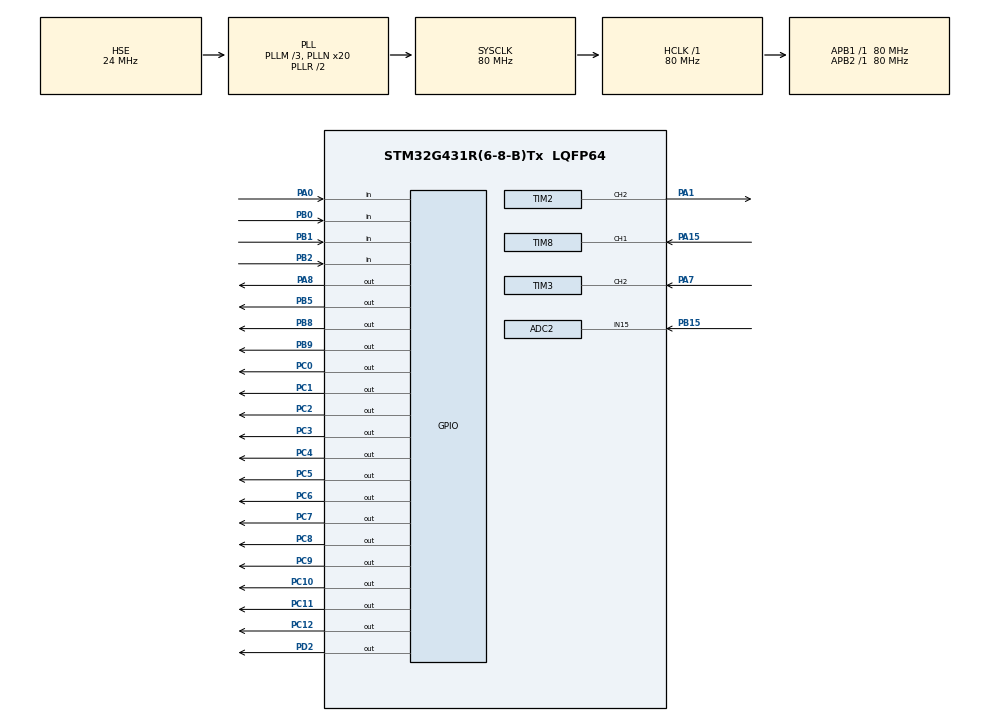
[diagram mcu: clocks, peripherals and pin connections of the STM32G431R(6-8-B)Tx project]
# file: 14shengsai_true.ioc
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ADC2.Channel-0\#ChannelRegularConversion=ADC_CHANNEL_15
ADC2.ClockPrescaler=ADC_CLOCK_ASYNC_DIV4
ADC2.ContinuousConvMode=ENABLE
ADC2.DMAContinuousRequests=ENABLE
ADC2.NbrOfConversionFlag=1
ADC2.OffsetNumber-0\#ChannelRegularConversion=ADC_OFFSET_NONE
ADC2.Rank-0\#ChannelRegularConversion=1
ADC2.SamplingTime-0\#ChannelRegularConversion=ADC_SAMPLETIME_2CYCLES_5
Dma.ADC2.0.Direction=DMA_PERIPH_TO_MEMORY
Dma.ADC2.0.EventEnable=DISABLE
Dma.ADC2.0.Instance=DMA1_Channel2
Dma.ADC2.0.MemDataAlignment=DMA_MDATAALIGN_WORD
Dma.ADC2.0.MemInc=DMA_MINC_ENABLE
Dma.ADC2.0.Mode=DMA_CIRCULAR
Dma.ADC2.0.PeriphDataAlignment=DMA_PDATAALIGN_WORD
Dma.ADC2.0.PeriphInc=DMA_PINC_DISABLE
Dma.ADC2.0.Polarity=HAL_DMAMUX_REQ_GEN_RISING
Dma.ADC2.0.Priority=DMA_PRIORITY_MEDIUM
Dma.ADC2.0.RequestNumber=1
Dma.ADC2.0.SignalID=NONE
Dma.ADC2.0.SyncEnable=DISABLE
Dma.ADC2.0.SyncPolarity=HAL_DMAMUX_SYNC_NO_EVENT
Dma.ADC2.0.SyncRequestNumber=1
Dma.ADC2.0.SyncSignalID=NONE
Dma.Request0=ADC2
Dma.Request1=TIM3_CH2
Dma.Request2=TIM8_CH1
Dma.TIM3_CH2.1.Direction=DMA_PERIPH_TO_MEMORY
Dma.TIM3_CH2.1.EventEnable=DISABLE
Dma.TIM3_CH2.1.Instance=DMA1_Channel1
Dma.TIM3_CH2.1.MemDataAlignment=DMA_MDATAALIGN_WORD
Dma.TIM3_CH2.1.MemInc=DMA_MINC_ENABLE
Dma.TIM3_CH2.1.Mode=DMA_CIRCULAR
Dma.TIM3_CH2.1.PeriphDataAlignment=DMA_PDATAALIGN_WORD
Dma.TIM3_CH2.1.PeriphInc=DMA_PINC_DISABLE
Dma.TIM3_CH2.1.Polarity=HAL_DMAMUX_REQ_GEN_RISING
Dma.TIM3_CH2.1.Priority=DMA_PRIORITY_LOW
Dma.TIM3_CH2.1.RequestNumber=1
Dma.TIM3_CH2.1.SignalID=NONE
Dma.TIM3_CH2.1.SyncEnable=DISABLE
Dma.TIM3_CH2.1.SyncPolarity=HAL_DMAMUX_SYNC_NO_EVENT
Dma.TIM3_CH2.1.SyncRequestNumber=1
Dma.TIM3_CH2.1.SyncSignalID=NONE
Dma.TIM8_CH1.2.Direction=DMA_PERIPH_TO_MEMORY
Dma.TIM8_CH1.2.EventEnable=DISABLE
Dma.TIM8_CH1.2.Instance=DMA1_Channel3
Dma.TIM8_CH1.2.MemDataAlignment=DMA_MDATAALIGN_WORD
Dma.TIM8_CH1.2.MemInc=DMA_MINC_ENABLE
Dma.TIM8_CH1.2.Mode=DMA_CIRCULAR
Dma.TIM8_CH1.2.PeriphDataAlignment=DMA_PDATAALIGN_WORD
Dma.TIM8_CH1.2.PeriphInc=DMA_PINC_DISABLE
Dma.TIM8_CH1.2.Polarity=HAL_DMAMUX_REQ_GEN_RISING
Dma.TIM8_CH1.2.Priority=DMA_PRIORITY_LOW
Dma.TIM8_CH1.2.RequestNumber=1
Dma.TIM8_CH1.2.SignalID=NONE
Dma.TIM8_CH1.2.SyncEnable=DISABLE
Dma.TIM8_CH1.2.SyncPolarity=HAL_DMAMUX_SYNC_NO_EVENT
Dma.TIM8_CH1.2.SyncRequestNumber=1
Dma.TIM8_CH1.2.SyncSignalID=NONE
Mcu.Family=STM32G4
Mcu.Name=STM32G431R(6-8-B)Tx
Mcu.Package=LQFP64
NVIC.ADC1_2_IRQn=true\:0\:0\:false\:false\:true\:true\:true\:true
NVIC.DMA1_Channel1_IRQn=true\:0\:0\:false\:false\:true\:false\:true\:true
NVIC.DMA1_Channel2_IRQn=true\:0\:0\:false\:false\:true\:false\:true\:true
NVIC.DMA1_Channel3_IRQn=true\:0\:0\:false\:false\:true\:false\:true\:true
NVIC.PriorityGroup=NVIC_PRIORITYGROUP_4
PA0.GPIO_PuPd=GPIO_PULLUP
PA0.Signal=GPIO_Input
PA1.Signal=S_TIM2_CH2
PA15.Signal=S_TIM8_CH1
PA7.Signal=S_TIM3_CH2
PA8.Signal=GPIO_Output
PB0.GPIO_PuPd=GPIO_PULLUP
PB0.Signal=GPIO_Input
PB1.GPIO_PuPd=GPIO_PULLUP
PB1.Signal=GPIO_Input
PB15.Mode=IN15-Single-Ended
PB15.Signal=ADC2_IN15
PB2.GPIO_PuPd=GPIO_PULLUP
PB2.Signal=GPIO_Input
PB5.Signal=GPIO_Output
PB8-BOOT0.Signal=GPIO_Output
PB9.Signal=GPIO_Output
PC0.Signal=GPIO_Output
PC1.Signal=GPIO_Output
PC10.Signal=GPIO_Output
PC11.Signal=GPIO_Output
PC12.Signal=GPIO_Output
PC2.Signal=GPIO_Output
PC3.Signal=GPIO_Output
PC4.Signal=GPIO_Output
PC5.Signal=GPIO_Output
PC6.Signal=GPIO_Output
PC7.Signal=GPIO_Output
PC8.Signal=GPIO_Output
PC9.Signal=GPIO_Output
PD2.Signal=GPIO_Output
PF0-OSC_IN.Mode=HSE-External-Oscillator
PF0-OSC_IN.Signal=RCC_OSC_IN
PF1-OSC_OUT.Mode=HSE-External-Oscillator
PF1-OSC_OUT.Signal=RCC_OSC_OUT
ProjectManager.HeapSize=0x200
ProjectManager.StackSize=0x400
ProjectManager.TargetToolchain=MDK-ARM V5.32
RCC.ADC12Freq_Value=80000000
RCC.AHBFreq_Value=80000000
RCC.APB1Freq_Value=80000000
RCC.APB1TimFreq_Value=80000000
RCC.APB2Freq_Value=80000000
RCC.APB2TimFreq_Value=80000000
RCC.CortexFreq_Value=80000000
RCC.EXTERNAL_CLOCK_VALUE=12288000
RCC.HCLKFreq_Value=80000000
RCC.HSE_VALUE=24000000
RCC.HSI48_VALUE=48000000
RCC.HSI_VALUE=16000000
RCC.LSE_VALUE=32768
RCC.PLLM=RCC_PLLM_DIV3
RCC.PLLN=20
RCC.PLLSourceVirtual=RCC_PLLSOURCE_HSE
RCC.SYSCLKFreq_VALUE=80000000
RCC.SYSCLKSource=RCC_SYSCLKSOURCE_PLLCLK
RCC.USBFreq_Value=80000000
RCC.VCOOutputFreq_Value=160000000
SH.S_TIM2_CH2.0=TIM2_CH2,PWM Generation2 CH2
SH.S_TIM3_CH2.0=TIM3_CH2,TriggerSource_TI2FP2
SH.S_TIM3_CH2.1=TIM3_CH2,Input_Capture2_from_TI2
SH.S_TIM8_CH1.0=TIM8_CH1,TriggerSource_TI1FP1
SH.S_TIM8_CH1.1=TIM8_CH1,Input_Capture1_from_TI1
TIM2.Channel-PWM\ Generation2\ CH2=TIM_CHANNEL_2
TIM2.PeriodNoDither=999
TIM2.Prescaler=79
TIM2.PulseNoDither_2=10
TIM3.Channel-Input_Capture2_from_TI2=TIM_CHANNEL_2
TIM3.Prescaler=79
TIM8.Channel-Input_Capture1_from_TI1=TIM_CHANNEL_1
TIM8.Prescaler=79
VP_SYS_VS_DBSignals.Mode=DisableDeadBatterySignals
VP_TIM2_VS_ClockSourceINT.Mode=Internal
VP_TIM3_VS_ClockSourceINT.Mode=Internal
VP_TIM3_VS_ControllerModeReset.Mode=Reset Mode
VP_TIM8_VS_ClockSourceINT.Mode=Internal
VP_TIM8_VS_ControllerModeReset.Mode=Reset Mode
board=custom

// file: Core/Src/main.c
/* USER CODE BEGIN Header */
/**
  ******************************************************************************
  * @file           : main.c
  * @brief          : Main program body
  ******************************************************************************
  * @attention
  *
  * Copyright (c) 2025 STMicroelectronics.
  * All rights reserved.
  *
  * This software is licensed under terms that can be found in the LICENSE file
  * in the root directory of this software component.
  * If no LICENSE file comes with this software, it is provided AS-IS.
  *
  ******************************************************************************
  */
/* USER CODE END Header */
#include "main.h"
#include "adc.h"
#include "dma.h"
#include "tim.h"
#include "gpio.h"
#include "bsp.h"

void SystemClock_Config(void);

int main(void)
{

  /* MCU Configuration--------------------------------------------------------*/

  /* Reset of all peripherals, Initializes the Flash interface and the Systick. */
  HAL_Init();

  /* Configure the system clock */
  SystemClock_Config();

  /* Initialize all configured peripherals */
  MX_GPIO_Init();
  MX_DMA_Init();
  MX_ADC2_Init();
  MX_TIM2_Init();
  MX_TIM3_Init();
  MX_TIM8_Init();
	scheduler_init();
  /* USER CODE BEGIN 2 */
LCD_Init();
LCD_Clear(Black);
LCD_SetBackColor(Black);
LCD_SetTextColor(White);
HAL_ADC_Start_DMA(&hadc2,(uint32_t*)&dma_buff[0][0],30);
HAL_TIM_IC_Start_DMA(&htim3,TIM_CHANNEL_2,tim_ic_buffer[0],64);//pa7,测量接收输入的频率
//HAL_TIM_IC_Start_DMA(&htim8,TIM_CHANNEL_1,tim_ic_buffer[0],64);//pa7换成了pa15
HAL_TIM_PWM_Start(&htim2,TIM_CHANNEL_2);//PA1,pwm输出
  /* USER CODE END 2 */

  /* Infinite loop */
  while (1)
  {
//key_proc();
//lcd_proc();
//ic_proc();
//adc_proc();
//led_proc();
		scheduler_run();
  }
}

void SystemClock_Config(void)
{
  RCC_OscInitTypeDef RCC_OscInitStruct = {0};
  RCC_ClkInitTypeDef RCC_ClkInitStruct = {0};

  /** Configure the main internal regulator output voltage
  */
  HAL_PWREx_ControlVoltageScaling(PWR_REGULATOR_VOLTAGE_SCALE1);

  /** Initializes the RCC Oscillators according to the specified parameters
  * in the RCC_OscInitTypeDef structure.
  */
  RCC_OscInitStruct.OscillatorType = RCC_OSCILLATORTYPE_HSE;
  RCC_OscInitStruct.HSEState = RCC_HSE_ON;
  RCC_OscInitStruct.PLL.PLLState = RCC_PLL_ON;
  RCC_OscInitStruct.PLL.PLLSource = RCC_PLLSOURCE_HSE;
  RCC_OscInitStruct.PLL.PLLM = RCC_PLLM_DIV3;
  RCC_OscInitStruct.PLL.PLLN = 20;
  RCC_OscInitStruct.PLL.PLLP = RCC_PLLP_DIV2;
  RCC_OscInitStruct.PLL.PLLQ = RCC_PLLQ_DIV2;
  RCC_OscInitStruct.PLL.PLLR = RCC_PLLR_DIV2;
  if (HAL_RCC_OscConfig(&RCC_OscInitStruct) != HAL_OK)
  {
    Error_Handler();
  }

  /** Initializes the CPU, AHB and APB buses clocks
  */
  RCC_ClkInitStruct.ClockType = RCC_CLOCKTYPE_HCLK|RCC_CLOCKTYPE_SYSCLK
                              |RCC_CLOCKTYPE_PCLK1|RCC_CLOCKTYPE_PCLK2;
  RCC_ClkInitStruct.SYSCLKSource = RCC_SYSCLKSOURCE_PLLCLK;
  RCC_ClkInitStruct.AHBCLKDivider = RCC_SYSCLK_DIV1;
  RCC_ClkInitStruct.APB1CLKDivider = RCC_HCLK_DIV1;
  RCC_ClkInitStruct.APB2CLKDivider = RCC_HCLK_DIV1;

  if (HAL_RCC_ClockConfig(&RCC_ClkInitStruct, FLASH_LATENCY_2) != HAL_OK)
  {
    Error_Handler();
  }
}

void Error_Handler(void)
{
  __disable_irq();
  while (1)
  {
  }
}
